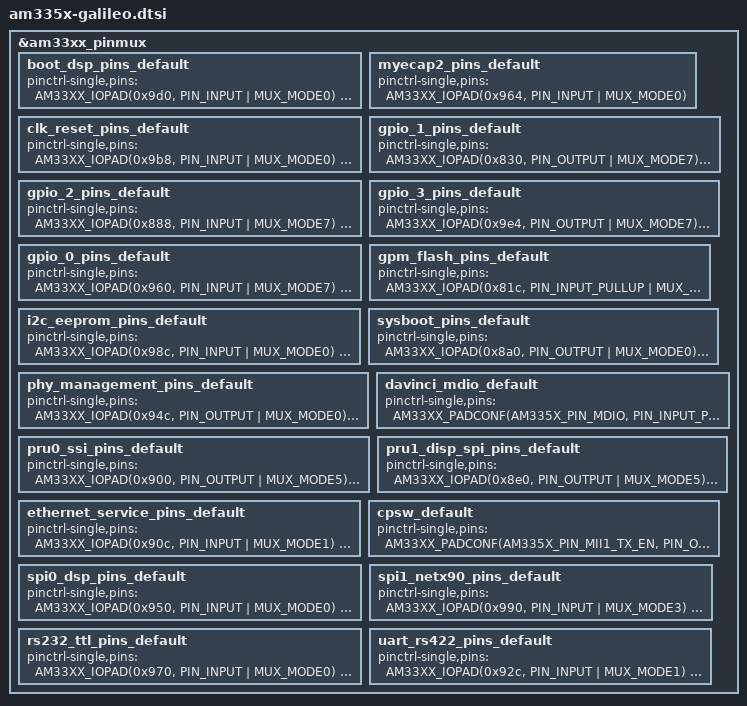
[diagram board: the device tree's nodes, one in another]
/* This file was auto-generated by TI PinMux on 14.1.2021 at 16:17:34. */
/* This file should only be used as a reference. Some pins/peripherals, */
/* depending on your use case, may need additional configuration. */

/* Some or all the pins from the following groups are not used by device tree 
   8-ch_adc
   emif_ddr3
   clk/reset
   osc_0
   osc_1
*/

&am33xx_pinmux {
	boot_dsp_pins_default: boot_dsp_pins_default {
		pinctrl-single,pins = <
			AM33XX_IOPAD(0x9d0, PIN_INPUT | MUX_MODE0) /* (C11) TMS.TMS */
			AM33XX_IOPAD(0x9d4, PIN_INPUT | MUX_MODE0) /* (B11) TDI.TDI */
			AM33XX_IOPAD(0x9d8, PIN_OUTPUT | MUX_MODE0) /* (A11) TDO.TDO */
			AM33XX_IOPAD(0x9dc, PIN_INPUT | MUX_MODE0) /* (A12) TCK.TCK */
			AM33XX_IOPAD(0x9e0, PIN_INPUT | MUX_MODE0) /* (B10) nTRST.nTRST */
		>;
	};


	myecap2_pins_default: myecap2_pins_default {
		pinctrl-single,pins = <
			AM33XX_IOPAD(0x964, PIN_INPUT | MUX_MODE0) /* (C18) eCAP0_in_PWM0_out.eCAP0_in_PWM0_out */
		>;
	};


	clk_reset_pins_default: clk_reset_pins_default {
		pinctrl-single,pins = <
			AM33XX_IOPAD(0x9b8, PIN_INPUT | MUX_MODE0) /* (A10) nRESETIN_OUT.nRESETIN_OUT */
			AM33XX_IOPAD(0x9c0, PIN_INPUT | MUX_MODE0) /* (B18) nNMI.nNMI */
			AM33XX_IOPAD(0x9b0, PIN_OUTPUT | MUX_MODE3) /* (A15) xdma_event_intr0.clkout1 */
			AM33XX_IOPAD(0x9b4, PIN_OUTPUT | MUX_MODE3) /* (D14) xdma_event_intr1.clkout2 */
		>;
	};


	gpio_1_pins_default: gpio_1_pins_default {
		pinctrl-single,pins = <
			AM33XX_IOPAD(0x830, PIN_OUTPUT | MUX_MODE7) /* (T12) gpmc_ad12.gpio1[12] */
			AM33XX_IOPAD(0x834, PIN_OUTPUT | MUX_MODE7) /* (R12) gpmc_ad13.gpio1[13] */
			AM33XX_IOPAD(0x838, PIN_OUTPUT | MUX_MODE7) /* (V13) gpmc_ad14.gpio1[14] */
			AM33XX_IOPAD(0x83c, PIN_OUTPUT| MUX_MODE7) /* (U13) gpmc_ad15.gpio1[15] */
			AM33XX_IOPAD(0x840, PIN_OUTPUT | MUX_MODE7) /* (R13) gpmc_a0.gpio1[16] */
			AM33XX_IOPAD(0x844, PIN_OUTPUT | MUX_MODE7) /* (V14) gpmc_a1.gpio1[17] */
			AM33XX_IOPAD(0x848, PIN_OUTPUT | MUX_MODE7) /* (U14) gpmc_a2.gpio1[18] */
			AM33XX_IOPAD(0x84c,PIN_OUTPUT | MUX_MODE7) /* (T14) gpmc_a3.gpio1[19] */
			AM33XX_IOPAD(0x850, PIN_OUTPUT | MUX_MODE7) /* (R14) gpmc_a4.gpio1[20] */
			AM33XX_IOPAD(0x854, PIN_OUTPUT | MUX_MODE7) /* (V15) gpmc_a5.gpio1[21] */
			AM33XX_IOPAD(0x858, PIN_OUTPUT | MUX_MODE7) /* (U15) gpmc_a6.gpio1[22] */
			AM33XX_IOPAD(0x85c, PIN_OUTPUT | MUX_MODE7) /* (T15) gpmc_a7.gpio1[23] */
			AM33XX_IOPAD(0x860, PIN_OUTPUT | MUX_MODE7) /* (V16) gpmc_a8.gpio1[24] */
			AM33XX_IOPAD(0x864, PIN_OUTPUT | MUX_MODE7) /* (U16) gpmc_a9.gpio1[25] */
			AM33XX_IOPAD(0x868, PIN_OUTPUT | MUX_MODE7) /* (T16) gpmc_a10.gpio1[26] */
			AM33XX_IOPAD(0x86c, PIN_OUTPUT| MUX_MODE7) /* (V17) gpmc_a11.gpio1[27] */
			AM33XX_IOPAD(0x878, PIN_OUTPUT | MUX_MODE7) /* (U18) gpmc_be1n.gpio1[28] */
			AM33XX_IOPAD(0x880, PIN_OUTPUT | MUX_MODE7) /* (U9) gpmc_csn1.gpio1[30] */
			AM33XX_IOPAD(0x884, PIN_OUTPUT| MUX_MODE7) /* (V9) gpmc_csn2.gpio1[31] */
		>;
	};



	gpio_2_pins_default: gpio_2_pins_default {
		pinctrl-single,pins = <
			AM33XX_IOPAD(0x888, PIN_INPUT | MUX_MODE7) /* (T13) gpmc_csn3.gpio2[0] */
			AM33XX_IOPAD(0x88c, PIN_INPUT | MUX_MODE7) /* (V12) gpmc_clk.gpio2[1] */
			AM33XX_IOPAD(0x8ec, PIN_INPUT | MUX_MODE7) /* (R6) lcd_ac_bias_en.gpio2[25] */
			AM33XX_IOPAD(0x8f0, PIN_INPUT | MUX_MODE7) /* (F17) mmc0_dat3.gpio2[26] */
			AM33XX_IOPAD(0x8f4, PIN_INPUT | MUX_MODE7) /* (F18) mmc0_dat2.gpio2[27] */
		>;
	};


	gpio_3_pins_default: gpio_3_pins_default {
		pinctrl-single,pins = <
			AM33XX_IOPAD(0x9e4, PIN_OUTPUT | MUX_MODE7) /* (C14) EMU0.gpio3[7] */
			AM33XX_IOPAD(0x9e8, PIN_INPUT | MUX_MODE7) /* (B14) EMU1.gpio3[8] */
			AM33XX_IOPAD(0xa34, PIN_INPUT | MUX_MODE7) /* (F15) USB1_DRVVBUS.gpio3[13] */
			AM33XX_IOPAD(0x9a0, PIN_INPUT | MUX_MODE7) /* (B12) mcasp0_aclkr.gpio3[18] */
			AM33XX_IOPAD(0x9a4, PIN_INPUT | MUX_MODE7) /* (C13) mcasp0_fsr.gpio3[19] */
			AM33XX_IOPAD(0x9a8, PIN_INPUT | MUX_MODE7) /* (D13) mcasp0_axr1.gpio3[20] */
			AM33XX_IOPAD(0x9ac, PIN_INPUT | MUX_MODE7) /* (A14) mcasp0_ahclkx.gpio3[21] */
		>;
	};



	gpio_0_pins_default: gpio_0_pins_default {
		pinctrl-single,pins = <
			AM33XX_IOPAD(0x960, PIN_INPUT | MUX_MODE7) /* (C15) spi0_cs1.gpio0[6] */
			AM33XX_IOPAD(0x978, PIN_INPUT | MUX_MODE7) /* (D18) uart1_ctsn.gpio0[12] */
			AM33XX_IOPAD(0x97c, PIN_INPUT | MUX_MODE7) /* (D17) uart1_rtsn.gpio0[13] */
			AM33XX_IOPAD(0x980, PIN_INPUT | MUX_MODE7) /* (D16) uart1_rxd.gpio0[14] */
			AM33XX_IOPAD(0x984, PIN_INPUT | MUX_MODE7) /* (D15) uart1_txd.gpio0[15] */
			AM33XX_IOPAD(0x91c, PIN_INPUT | MUX_MODE7) /* (J18) gmii1_txd3.gpio0[16] */
			AM33XX_IOPAD(0x820, PIN_INPUT | MUX_MODE7) /* (U10) gpmc_ad8.gpio0[22] */
			AM33XX_IOPAD(0x824, PIN_INPUT | MUX_MODE7) /* (T10) gpmc_ad9.gpio0[23] */
			AM33XX_IOPAD(0x828, PIN_INPUT | MUX_MODE7) /* (T11) gpmc_ad10.gpio0[26] */
			AM33XX_IOPAD(0x82c, PIN_INPUT | MUX_MODE7) /* (U12) gpmc_ad11.gpio0[27] */
		>;
	};


	gpm_flash_pins_default: gpm_flash_pins_default {
		pinctrl-single,pins = <
			AM33XX_IOPAD(0x81c, PIN_INPUT_PULLUP | MUX_MODE0) /* (T9) gpmc_ad7.gpmc_ad7 */
			AM33XX_IOPAD(0x818, PIN_INPUT_PULLUP | MUX_MODE0) /* (R9) gpmc_ad6.gpmc_ad6 */
			AM33XX_IOPAD(0x814, PIN_INPUT_PULLUP | MUX_MODE0) /* (V8) gpmc_ad5.gpmc_ad5 */
			AM33XX_IOPAD(0x810, PIN_INPUT_PULLUP | MUX_MODE0) /* (U8) gpmc_ad4.gpmc_ad4 */
			AM33XX_IOPAD(0x80c, PIN_INPUT_PULLUP | MUX_MODE0) /* (T8) gpmc_ad3.gpmc_ad3 */
			AM33XX_IOPAD(0x808, PIN_INPUT_PULLUP | MUX_MODE0) /* (R8) gpmc_ad2.gpmc_ad2 */
			AM33XX_IOPAD(0x804, PIN_INPUT_PULLUP | MUX_MODE0) /* (V7) gpmc_ad1.gpmc_ad1 */
			AM33XX_IOPAD(0x800, PIN_INPUT_PULLUP | MUX_MODE0) /* (U7) gpmc_ad0.gpmc_ad0 */
			AM33XX_IOPAD(0x870, PIN_INPUT_PULLUP | MUX_MODE0) /* (T17) gpmc_wait0.gpmc_wait0 */
			AM33XX_IOPAD(0x874, PIN_OUTPUT | MUX_MODE0) /* (U17) gpmc_wpn.gpmc_wpn */
			AM33XX_IOPAD(0x87c, PIN_OUTPUT | MUX_MODE0) /* (V6) gpmc_csn0.gpmc_csn0 */
			AM33XX_IOPAD(0x890, PIN_OUTPUT | MUX_MODE0) /* (R7) gpmc_advn_ale.gpmc_advn_ale */
			AM33XX_IOPAD(0x894, PIN_OUTPUT | MUX_MODE0) /* (T7) gpmc_oen_ren.gpmc_oen_ren */
			AM33XX_IOPAD(0x898, PIN_OUTPUT | MUX_MODE0) /* (U6) gpmc_wen.gpmc_wen */
			AM33XX_IOPAD(0x89c, PIN_OUTPUT | MUX_MODE0) /* (T6) gpmc_be0n_cle.gpmc_be0n_cle */
		>;
	};

	i2c_eeprom_pins_default: i2c_eeprom_pins_default {
		pinctrl-single,pins = <
			AM33XX_IOPAD(0x98c, PIN_INPUT | MUX_MODE0) /* (C16) I2C0_SCL.I2C0_SCL */
			AM33XX_IOPAD(0x988, PIN_INPUT | MUX_MODE0) /* (C17) I2C0_SDA.I2C0_SDA */
		>;
	};



	sysboot_pins_default: sysboot_pins_default {
		pinctrl-single,pins = <
			AM33XX_IOPAD(0x8a0, PIN_OUTPUT | MUX_MODE0) /* (R1) lcd_data0.lcd_data0 */
			AM33XX_IOPAD(0x8a4, PIN_OUTPUT | MUX_MODE0) /* (R2) lcd_data1.lcd_data1 */
			AM33XX_IOPAD(0x8a8, PIN_OUTPUT | MUX_MODE0) /* (R3) lcd_data2.lcd_data2 */
			AM33XX_IOPAD(0x8ac, PIN_OUTPUT | MUX_MODE0) /* (R4) lcd_data3.lcd_data3 */
			AM33XX_IOPAD(0x8b0, PIN_OUTPUT | MUX_MODE0) /* (T1) lcd_data4.lcd_data4 */
			AM33XX_IOPAD(0x8b4, PIN_OUTPUT | MUX_MODE0) /* (T2) lcd_data5.lcd_data5 */
			AM33XX_IOPAD(0x8b8, PIN_OUTPUT | MUX_MODE0) /* (T3) lcd_data6.lcd_data6 */
			AM33XX_IOPAD(0x8bc, PIN_OUTPUT | MUX_MODE0) /* (T4) lcd_data7.lcd_data7 */
			AM33XX_IOPAD(0x8c0, PIN_OUTPUT | MUX_MODE0) /* (U1) lcd_data8.lcd_data8 */
			AM33XX_IOPAD(0x8c4, PIN_OUTPUT | MUX_MODE0) /* (U2) lcd_data9.lcd_data9 */
			AM33XX_IOPAD(0x8c8, PIN_OUTPUT | MUX_MODE0) /* (U3) lcd_data10.lcd_data10 */
			AM33XX_IOPAD(0x8cc, PIN_OUTPUT | MUX_MODE0) /* (U4) lcd_data11.lcd_data11 */
			AM33XX_IOPAD(0x8d0, PIN_OUTPUT | MUX_MODE0) /* (V2) lcd_data12.lcd_data12 */
			AM33XX_IOPAD(0x8d4, PIN_OUTPUT | MUX_MODE0) /* (V3) lcd_data13.lcd_data13 */
			AM33XX_IOPAD(0x8d8, PIN_OUTPUT | MUX_MODE0) /* (V4) lcd_data14.lcd_data14 */
			AM33XX_IOPAD(0x8dc, PIN_OUTPUT | MUX_MODE0) /* (T5) lcd_data15.lcd_data15 */
		>;
	};



	phy_management_pins_default: phy_management_pins_default {
		pinctrl-single,pins = <
			AM33XX_IOPAD(0x94c, PIN_OUTPUT | MUX_MODE0) /* (M18) mdio_clk.mdio_clk */
			AM33XX_IOPAD(0x948, PIN_INPUT_PULLUP | SLEWCTRL_FAST | MUX_MODE0) /* (M17) mdio_data.mdio_data */
		>;
	};

	davinci_mdio_default: davinci_mdio_default {
		pinctrl-single,pins = <
			AM33XX_PADCONF(AM335X_PIN_MDIO, PIN_INPUT_PULLUP | SLEWCTRL_FAST, MUX_MODE0)
			AM33XX_PADCONF(AM335X_PIN_MDC, PIN_OUTPUT_PULLUP, MUX_MODE0)
		>;
	};


	pru0_ssi_pins_default: pru0_ssi_pins_default {
		pinctrl-single,pins = <
			AM33XX_IOPAD(0x900, PIN_OUTPUT | MUX_MODE5) /* (G17) mmc0_clk.pr1_pru0_pru_r30[12] */
			AM33XX_IOPAD(0x904, PIN_OUTPUT | MUX_MODE5) /* (G18) mmc0_cmd.pr1_pru0_pru_r30[13] */
		>;
	};



	pru1_disp_spi_pins_default: pru1_disp_spi_pins_default {
		pinctrl-single,pins = <
			AM33XX_IOPAD(0x8e0, PIN_OUTPUT | MUX_MODE5) /* (U5) lcd_vsync.pr1_pru1_pru_r30[8] */
			AM33XX_IOPAD(0x8e4, PIN_OUTPUT | MUX_MODE5) /* (R5) lcd_hsync.pr1_pru1_pru_r30[9] */
			AM33XX_IOPAD(0x8e8, PIN_OUTPUT | MUX_MODE5) /* (V5) lcd_pclk.pr1_pru1_pru_r30[10] */
		>;
	};


	ethernet_service_pins_default: ethernet_service_pins_default {
		pinctrl-single,pins = <
			AM33XX_IOPAD(0x90c, PIN_INPUT | MUX_MODE1) /* (H17) gmii1_crs.rmii1_crs_dv */
			AM33XX_IOPAD(0x910, PIN_INPUT | MUX_MODE1) /* (J15) gmii1_rxer.rmii1_rxer */
			AM33XX_IOPAD(0x914, PIN_OUTPUT | MUX_MODE1) /* (J16) gmii1_txen.rmii1_txen */
			AM33XX_IOPAD(0x928, PIN_OUTPUT | MUX_MODE1) /* (K17) gmii1_txd0.rmii1_txd0 */
			AM33XX_IOPAD(0x924, PIN_OUTPUT | MUX_MODE1) /* (K16) gmii1_txd1.rmii1_txd1 */
			AM33XX_IOPAD(0x940, PIN_INPUT | MUX_MODE1) /* (M16) gmii1_rxd0.rmii1_rxd0 */
			AM33XX_IOPAD(0x93c, PIN_INPUT | MUX_MODE1) /* (L15) gmii1_rxd1.rmii1_rxd1 */
			AM33XX_IOPAD(0x944, PIN_INPUT | MUX_MODE0) /* (H18) rmii1_refclk.rmii1_refclk */
		>;
	};

		cpsw_default: cpsw_default {
		pinctrl-single,pins = <
			/* Slave 1 */
			/* mii1_tx_en.rgmii1_tctl */
			AM33XX_PADCONF(AM335X_PIN_MII1_TX_EN, PIN_OUTPUT_PULLDOWN, MUX_MODE1)
			/* mii1_rxdv.rgmii1_rctl */
			AM33XX_PADCONF(AM335X_PIN_MII1_RX_DV, PIN_INPUT_PULLDOWN, MUX_MODE1)
			/* mii1_txd1.rgmii1_td1 */
			AM33XX_PADCONF(AM335X_PIN_MII1_TXD1, PIN_OUTPUT_PULLDOWN, MUX_MODE1)
			/* mii1_txd0.rgmii1_td0 */
			AM33XX_PADCONF(AM335X_PIN_MII1_TXD0, PIN_OUTPUT_PULLDOWN, MUX_MODE1)
			/* mii1_txclk.rgmii1_tclk */
			AM33XX_PADCONF(AM335X_PIN_MII1_TX_CLK, PIN_OUTPUT_PULLDOWN, MUX_MODE0)
			/* mii1_rxclk.rgmii1_rclk */
			AM33XX_PADCONF(AM335X_PIN_MII1_RX_CLK, PIN_INPUT_PULLDOWN, MUX_MODE0)
			/* mii1_rxd1.rgmii1_rd1 */
			AM33XX_PADCONF(AM335X_PIN_MII1_RXD1, PIN_INPUT_PULLDOWN, MUX_MODE1)
			/* mii1_rxd0.rgmii1_rd0 */
			AM33XX_PADCONF(AM335X_PIN_MII1_RXD0, PIN_INPUT_PULLDOWN, MUX_MODE1)
		>;
	};


	spi0_dsp_pins_default: spi0_dsp_pins_default {
		pinctrl-single,pins = <
			AM33XX_IOPAD(0x950, PIN_INPUT | MUX_MODE0) /* (A17) spi0_sclk.spi0_sclk */
			AM33XX_IOPAD(0x954, PIN_INPUT | MUX_MODE0) /* (B17) spi0_d0.spi0_d0 */
			AM33XX_IOPAD(0x958, PIN_INPUT | MUX_MODE0) /* (B16) spi0_d1.spi0_d1 */
			AM33XX_IOPAD(0x95c, PIN_INPUT | MUX_MODE0) /* (A16) spi0_cs0.spi0_cs0 */
		>;
	};


	spi1_netx90_pins_default: spi1_netx90_pins_default {
		pinctrl-single,pins = <
			AM33XX_IOPAD(0x990, PIN_INPUT | MUX_MODE3) /* (A13) mcasp0_aclkx.spi1_sclk */
			AM33XX_IOPAD(0x994, PIN_INPUT | MUX_MODE3) /* (B13) mcasp0_fsx.spi1_d0 */
			AM33XX_IOPAD(0x998, PIN_INPUT | MUX_MODE3) /* (D12) mcasp0_axr0.spi1_d1 */
			AM33XX_IOPAD(0x99c, PIN_INPUT | MUX_MODE3) /* (C12) mcasp0_ahclkr.spi1_cs0 */
		>;
	};


	rs232_ttl_pins_default: rs232_ttl_pins_default {
		pinctrl-single,pins = <
			AM33XX_IOPAD(0x970, PIN_INPUT | MUX_MODE0) /* (E15) uart0_rxd.uart0_rxd */
			AM33XX_IOPAD(0x974, PIN_OUTPUT | MUX_MODE0) /* (E16) uart0_txd.uart0_txd */
		>;
	};


	uart_rs422_pins_default: uart_rs422_pins_default {
		pinctrl-single,pins = <
			AM33XX_IOPAD(0x92c, PIN_INPUT | MUX_MODE1) /* (K18) gmii1_txclk.uart2_rxd */
			AM33XX_IOPAD(0x930, PIN_OUTPUT | MUX_MODE1) /* (L18) gmii1_rxclk.uart2_txd */
		>;
	};

};
